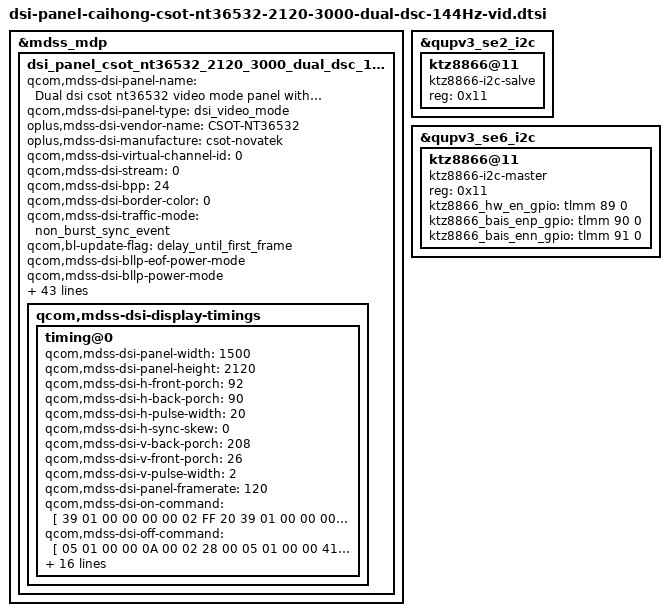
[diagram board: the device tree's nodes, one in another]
&mdss_mdp {
	dsi_panel_csot_nt36532_2120_3000_dual_dsc_144hz_vid: qcom,mdss_dsi_panel_csot_nt36532_2120_3000_dual_dsc_144hz_vid {
		qcom,mdss-dsi-panel-name = "Dual dsi csot nt36532 video mode panel with DSC";
		qcom,mdss-dsi-panel-type = "dsi_video_mode";
		oplus,mdss-dsi-vendor-name = "CSOT-NT36532";
		oplus,mdss-dsi-manufacture = "csot-novatek";
		qcom,mdss-dsi-virtual-channel-id = <0>;
		qcom,mdss-dsi-stream = <0>;
		qcom,mdss-dsi-bpp = <24>;
		qcom,mdss-dsi-border-color = <0>;
		qcom,mdss-dsi-traffic-mode = "non_burst_sync_event";
		qcom,bl-update-flag = "delay_until_first_frame";
		qcom,mdss-dsi-bllp-eof-power-mode;
		qcom,mdss-dsi-bllp-power-mode;
		qcom,mdss-dsi-lane-0-state;
		qcom,mdss-dsi-lane-1-state;
		qcom,mdss-dsi-lane-2-state;
		qcom,mdss-dsi-lane-3-state;
		qcom,mdss-dsi-dma-trigger = "trigger_sw";
		qcom,mdss-dsi-mdp-trigger = "none";
		qcom,mdss-dsi-tx-eot-append;
		qcom,mdss-dsi-lp11-init;
		qcom,mdss-dsi-reset-sequence = <1 10>, <0 5>, <1 10>;
		qcom,mdss-pan-physical-width-dimension = <250>;
		qcom,mdss-pan-physical-height-dimension = <177>;
		/* HDR Setting */
		qcom,mdss-dsi-panel-hdr-enabled;
		qcom,mdss-dsi-panel-hdr-color-primaries = <15635 16450 34000 16000 13250 34500 7500 3000>;
		qcom,mdss-dsi-panel-peak-brightness = <5400000>;
		qcom,mdss-dsi-panel-average-brightness = <2000000>;
		qcom,mdss-dsi-panel-blackness-level = <2047>;

		qcom,mdss-dsi-display-timings {
			timing@0 {
				qcom,mdss-dsi-panel-width = <1500>;
				qcom,mdss-dsi-panel-height = <2120>;
				qcom,mdss-dsi-h-front-porch = <92>;
				qcom,mdss-dsi-h-back-porch = <90>;
				qcom,mdss-dsi-h-pulse-width = <20>;
				qcom,mdss-dsi-h-sync-skew = <0>;
				qcom,mdss-dsi-v-back-porch = <208>;
				qcom,mdss-dsi-v-front-porch = <26>;
				qcom,mdss-dsi-v-pulse-width = <2>;
				qcom,mdss-dsi-panel-framerate = <120>;

				qcom,mdss-dsi-on-command = [
					39 01 00 00 00 00 02 FF 20
					39 01 00 00 00 00 02 FB 01
					39 01 00 00 00 00 02 0D 43
					39 01 00 00 00 00 02 32 72
					39 01 00 00 00 00 02 44 48
					39 01 00 00 00 00 02 58 43
					39 01 00 00 00 00 02 62 36
					39 01 00 00 00 00 02 63 A4
					39 01 00 00 00 00 02 65 CC
					39 01 00 00 00 00 02 69 DD
					39 01 00 00 00 00 02 6D CC
					39 01 00 00 00 00 02 78 93
					39 01 00 00 00 00 02 7C 22
					39 01 00 00 00 00 02 89 6F
					39 01 00 00 00 00 02 8A 6F
					39 01 00 00 00 00 02 8D 6F
					39 01 00 00 00 00 0D EC 4B 4B 4B 4B 5A 5A 5A 5A E1 E1 E1 E1
					39 01 00 00 00 00 02 FF 21
					39 01 00 00 00 00 02 FB 01
					39 01 00 00 00 00 02 BC 00
					39 01 00 00 00 00 02 FF 22
					39 01 00 00 00 00 02 FB 01
					39 01 00 00 00 00 02 6E 13
					39 01 00 00 00 00 02 6F 09
					39 01 00 00 00 00 02 70 97
					39 01 00 00 00 00 02 71 09
					39 01 00 00 00 00 02 73 09
					39 01 00 00 00 00 02 75 7F
					39 01 00 00 00 00 02 76 09
					39 01 00 00 00 00 02 8A 09
					39 01 00 00 00 00 02 8C 09
					39 01 00 00 00 00 02 8E F3
					39 01 00 00 00 00 02 8F 23
					39 01 00 00 00 00 02 90 23
					39 01 00 00 00 00 02 91 23
					39 01 00 00 00 00 02 92 23
					39 01 00 00 00 00 02 93 23
					39 01 00 00 00 00 02 94 0A
					39 01 00 00 00 00 02 95 0A
					39 01 00 00 00 00 02 96 20
					39 01 00 00 00 00 02 9C 0A
					39 01 00 00 00 00 02 9D 20
					39 01 00 00 00 00 02 9E 0A
					39 01 00 00 00 00 02 9F 6A
					39 01 00 00 00 00 02 A0 0B
					39 01 00 00 00 00 02 A6 06
					39 01 00 00 00 00 02 A9 50
					39 01 00 00 00 00 02 AA AD
					39 01 00 00 00 00 02 AB B1
					39 01 00 00 00 00 02 AD 10
					39 01 00 00 00 00 05 B0 0E 0F 0F 0F
					39 01 00 00 00 00 05 B1 ED 63 63 63
					39 01 00 00 00 00 05 B2 0E 0E 0E 0E
					39 01 00 00 00 00 05 B3 11 87 87 87
					39 01 00 00 00 00 05 B4 0E 0F 0F 0F
					39 01 00 00 00 00 05 B5 E9 5F 5F 5F
					39 01 00 00 00 00 02 B8 03
					39 01 00 00 00 00 02 B9 60
					39 01 00 00 00 00 02 BA 60
					39 01 00 00 00 00 02 BB 60
					39 01 00 00 00 00 02 BC 02
					39 01 00 00 00 00 02 BD 60
					39 01 00 00 00 00 02 BE 0B
					39 01 00 00 00 00 02 BF 60
					39 01 00 00 00 00 02 C1 60
					39 01 00 00 00 00 02 C2 06
					39 01 00 00 00 00 02 C3 60
					39 01 00 00 00 00 02 C6 02
					39 01 00 00 00 00 02 C7 58
					39 01 00 00 00 00 02 CA 0A
					39 01 00 00 00 00 02 CB 58
					39 01 00 00 00 00 02 CF 0A
					39 01 00 00 00 00 02 D0 58
					39 01 00 00 00 00 02 D3 0A
					39 01 00 00 00 00 02 D4 58
					39 01 00 00 00 00 02 D8 0B
					39 01 00 00 00 00 02 D9 59
					39 01 00 00 00 00 02 DC 0B
					39 01 00 00 00 00 02 DD 59
					39 01 00 00 00 00 02 E1 0B
					39 01 00 00 00 00 02 E2 59
					39 01 00 00 00 00 02 E6 02
					39 01 00 00 00 00 02 E7 58
					39 01 00 00 00 00 02 EA 0B
					39 01 00 00 00 00 02 EB 59
					39 01 00 00 00 00 02 F3 02
					39 01 00 00 00 00 02 F4 58
					39 01 00 00 00 00 02 F8 FF
					39 01 00 00 00 00 02 F9 FF
					39 01 00 00 00 00 02 FF 23
					39 01 00 00 00 00 02 FB 01
					39 01 00 00 00 00 02 6B 20
					39 01 00 00 00 00 02 6C 0A
					39 01 00 00 00 00 02 6D 20
					39 01 00 00 00 00 02 73 0A
					39 01 00 00 00 00 02 74 0A
					39 01 00 00 00 00 03 75 00 00
					39 01 00 00 00 00 03 76 01 02
					39 01 00 00 00 00 03 77 01 02
					39 01 00 00 00 00 03 78 01 02
					39 01 00 00 00 00 03 7A 63 63
					39 01 00 00 00 00 03 7B B3 B3
					39 01 00 00 00 00 03 7C 2D 32
					39 01 00 00 00 00 03 7E 10 10
					39 01 00 00 00 00 03 BA AD 00
					39 01 00 00 00 00 03 BB AB 00
					39 01 00 00 00 00 04 BC 41 00 00
					39 01 00 00 00 00 02 FF 24
					39 01 00 00 00 00 02 FB 01
					39 01 00 00 00 00 11 00 0C 0D 0E 0F 10 11 12 13 03 25 04 26 27 25 03 24
					39 01 00 00 00 00 09 01 28 03 2C 2E 2C 2E 03 03
					39 01 00 00 00 00 11 02 0C 0D 0E 0F 10 11 12 13 03 25 04 26 27 25 03 24
					39 01 00 00 00 00 09 03 28 03 2C 2E 2C 2E 03 03
					39 01 00 00 00 00 02 1C 80
					39 01 00 00 00 00 02 2F 03
					39 01 00 00 00 00 02 30 03
					39 01 00 00 00 00 02 31 52
					39 01 00 00 00 00 02 33 06
					39 01 00 00 00 00 02 34 07
					39 01 00 00 00 00 02 35 12
					39 01 00 00 00 00 02 37 24
					39 01 00 00 00 00 02 3B 57
					39 01 00 00 00 00 02 3D 01
					39 01 00 00 00 00 02 3F 0B
					39 01 00 00 00 00 02 4B 47
					39 01 00 00 00 00 02 4C 01
					39 01 00 00 00 00 02 50 87
					39 01 00 00 00 00 02 51 21
					39 01 00 00 00 00 02 52 43
					39 01 00 00 00 00 02 53 65
					39 01 00 00 00 00 02 54 87
					39 01 00 00 00 00 03 55 02 01
					39 01 00 00 00 00 02 56 08
					39 01 00 00 00 00 02 58 10
					39 01 00 00 00 00 02 59 10
					39 01 00 00 00 00 02 5A 09
					39 01 00 00 00 00 02 5B 53
					39 01 00 00 00 00 03 5E 00 06
					39 01 00 00 00 00 03 60 81 77
					39 01 00 00 00 00 02 61 48
					39 01 00 00 00 00 02 67 21
					39 01 00 00 00 00 02 68 43
					39 01 00 00 00 00 02 6B 34
					39 01 00 00 00 00 02 6C 12
					39 01 00 00 00 00 02 71 04
					39 01 00 00 00 00 02 7E 20
					39 01 00 00 00 00 02 7F E1
					39 01 00 00 00 00 04 92 5E 00 FE
					39 01 00 00 00 00 03 93 1A 00
					39 01 00 00 00 00 03 94 D2 00
					39 01 00 00 00 00 02 95 09
					39 01 00 00 00 00 04 96 20 AA 00
					39 01 00 00 00 00 02 97 C0
					39 01 00 00 00 00 02 98 80
					39 01 00 00 00 00 02 9A 0A
					39 01 00 00 00 00 02 A5 00
					39 01 00 00 00 00 04 AA A9 A9 2A
					39 01 00 00 00 00 02 AB 26
					39 01 00 00 00 00 04 B6 08 08 00
					39 01 00 00 00 00 04 C2 CC 00 01
					39 01 00 00 00 00 02 C3 00
					39 01 00 00 00 00 02 C4 2F
					39 01 00 00 00 00 02 D4 03
					39 01 00 00 00 00 02 D6 46
					39 01 00 00 00 00 02 D7 25
					39 01 00 00 00 00 02 D9 21
					39 01 00 00 00 00 02 DB 39
					39 01 00 00 00 00 02 DD 44
					39 01 00 00 00 00 02 DF 09
					39 01 00 00 00 00 02 E1 09
					39 01 00 00 00 00 02 E3 09
					39 01 00 00 00 00 02 E5 09
					39 01 00 00 00 00 02 E9 09
					39 01 00 00 00 00 02 EB 09
					39 01 00 00 00 00 02 EF 09
					39 01 00 00 00 00 02 F1 23
					39 01 00 00 00 00 02 F2 23
					39 01 00 00 00 00 02 F3 23
					39 01 00 00 00 00 02 F4 22
					39 01 00 00 00 00 02 F5 23
					39 01 00 00 00 00 02 F6 23
					39 01 00 00 00 00 02 FF 25
					39 01 00 00 00 00 02 FB 01
					39 01 00 00 00 00 02 05 00
					39 01 00 00 00 00 02 0F 20
					39 01 00 00 00 00 02 13 01
					39 01 00 00 00 00 02 14 FD
					39 01 00 00 00 00 02 15 01
					39 01 00 00 00 00 02 16 A8
					39 01 00 00 00 00 02 1F 09
					39 01 00 00 00 00 02 20 53
					39 01 00 00 00 00 02 23 0A
					39 01 00 00 00 00 02 24 20
					39 01 00 00 00 00 02 26 09
					39 01 00 00 00 00 02 27 53
					39 01 00 00 00 00 02 2A 0A
					39 01 00 00 00 00 02 2B 20
					39 01 00 00 00 00 02 31 20
					39 01 00 00 00 00 02 33 0B
					39 01 00 00 00 00 02 34 58
					39 01 00 00 00 00 02 37 0A
					39 01 00 00 00 00 02 38 20
					39 01 00 00 00 00 02 39 0A
					39 01 00 00 00 00 02 3A 02
					39 01 00 00 00 00 02 3F 20
					39 01 00 00 00 00 02 40 00
					39 01 00 00 00 00 02 42 0A
					39 01 00 00 00 00 02 45 57
					39 01 00 00 00 00 02 47 47
					39 01 00 00 00 00 02 48 0B
					39 01 00 00 00 00 02 49 58
					39 01 00 00 00 00 02 4C 0A
					39 01 00 00 00 00 02 4D 20
					39 01 00 00 00 00 02 4E 0A
					39 01 00 00 00 00 02 50 0B
					39 01 00 00 00 00 02 51 58
					39 01 00 00 00 00 02 54 0A
					39 01 00 00 00 00 02 55 20
					39 01 00 00 00 00 02 56 0A
					39 01 00 00 00 00 02 5B A0
					39 01 00 00 00 00 02 5E 57
					39 01 00 00 00 00 02 60 47
					39 01 00 00 00 00 02 61 0B
					39 01 00 00 00 00 02 62 58
					39 01 00 00 00 00 02 65 0A
					39 01 00 00 00 00 02 66 20
					39 01 00 00 00 00 02 67 0A
					39 01 00 00 00 00 02 68 06
					39 01 00 00 00 00 02 6A 06
					39 01 00 00 00 00 02 6B 04
					39 01 00 00 00 00 02 6C 0E
					39 01 00 00 00 00 02 6D 0E
					39 01 00 00 00 00 02 6E 12
					39 01 00 00 00 00 02 6F 12
					39 01 00 00 00 00 02 BC 01
					39 01 00 00 00 00 02 BD FD
					39 01 00 00 00 00 02 C0 0C
					39 01 00 00 00 00 02 C1 46
					39 01 00 00 00 00 02 C2 A5
					39 01 00 00 00 00 02 C5 1F
					39 01 00 00 00 00 02 C6 10
					39 01 00 00 00 00 02 DB 03
					39 01 00 00 00 00 02 DC 18
					39 01 00 00 00 00 02 DD 02
					39 01 00 00 00 00 02 DE 94
					39 01 00 00 00 00 02 ED 80
					39 01 00 00 00 00 02 F6 03
					39 01 00 00 00 00 02 F7 18
					39 01 00 00 00 00 02 FF 26
					39 01 00 00 00 00 02 FB 01
					39 01 00 00 00 00 02 04 6A
					39 01 00 00 00 00 02 06 9B
					39 01 00 00 00 00 02 0A 05
					39 01 00 00 00 00 02 0C 06
					39 01 00 00 00 00 02 0D 03
					39 01 00 00 00 00 02 0F 00
					39 01 00 00 00 00 02 11 05
					39 01 00 00 00 00 02 12 51
					39 01 00 00 00 00 02 13 30
					39 01 00 00 00 00 02 14 28
					39 01 00 00 00 00 02 16 11
					39 01 00 00 00 00 05 19 20 1F 20 20
					39 01 00 00 00 00 05 1A 70 75 70 70
					39 01 00 00 00 00 05 1B 1F 1E 1F 1F
					39 01 00 00 00 00 05 1C 8F 94 8F 8F
					39 01 00 00 00 00 02 1D 00
					39 01 00 00 00 00 02 1E 5E
					39 01 00 00 00 00 02 1F 5E
					39 01 00 00 00 00 02 24 02
					39 01 00 00 00 00 02 25 5E
					39 01 00 00 00 00 02 26 26
					39 01 00 00 00 00 05 2A 20 1F 20 20
					39 01 00 00 00 00 05 2B 67 6C 67 67
					39 01 00 00 00 00 0A 2D 00 00 00 0E 00 00 0F 04 00
					39 01 00 00 00 00 02 2F 0B
					39 01 00 00 00 00 02 30 5E
					39 01 00 00 00 00 02 32 5E
					39 01 00 00 00 00 02 33 22
					39 01 00 00 00 00 02 34 92
					39 01 00 00 00 00 02 35 78
					39 01 00 00 00 00 02 36 96
					39 01 00 00 00 00 02 37 78
					39 01 00 00 00 00 02 38 06
					39 01 00 00 00 00 02 39 06
					39 01 00 00 00 00 02 3A 5E
					39 01 00 00 00 00 07 3D 00 A0 2A 00 00 00
					39 01 00 00 00 00 02 40 5A
					39 01 00 00 00 00 02 41 5A
					39 01 00 00 00 00 02 42 5A
					39 01 00 00 00 00 02 43 02
					39 01 00 00 00 00 02 44 5A
					39 01 00 00 00 00 02 45 0B
					39 01 00 00 00 00 02 46 5A
					39 01 00 00 00 00 02 48 5A
					39 01 00 00 00 00 02 49 06
					39 01 00 00 00 00 02 4A 5A
					39 01 00 00 00 00 02 4D 02
					39 01 00 00 00 00 02 4E 51
					39 01 00 00 00 00 02 4F 02
					39 01 00 00 00 00 02 50 47
					39 01 00 00 00 00 02 51 0A
					39 01 00 00 00 00 02 52 51
					39 01 00 00 00 00 02 53 02
					39 01 00 00 00 00 02 54 72
					39 01 00 00 00 00 02 56 0A
					39 01 00 00 00 00 02 58 51
					39 01 00 00 00 00 02 5B 0A
					39 01 00 00 00 00 02 5C 51
					39 01 00 00 00 00 02 60 0B
					39 01 00 00 00 00 02 61 52
					39 01 00 00 00 00 02 64 0B
					39 01 00 00 00 00 02 65 52
					39 01 00 00 00 00 02 69 0B
					39 01 00 00 00 00 02 6A 52
					39 01 00 00 00 00 02 6E 02
					39 01 00 00 00 00 02 6F 51
					39 01 00 00 00 00 02 70 02
					39 01 00 00 00 00 02 71 47
					39 01 00 00 00 00 02 72 0B
					39 01 00 00 00 00 02 73 52
					39 01 00 00 00 00 02 74 02
					39 01 00 00 00 00 02 75 72
					39 01 00 00 00 00 02 7B 02
					39 01 00 00 00 00 02 7C 51
					39 01 00 00 00 00 02 7E 02
					39 01 00 00 00 00 02 7F 47
					39 01 00 00 00 00 02 80 CC
					39 01 00 00 00 00 02 81 CC
					39 01 00 00 00 00 05 82 00 64 64 64
					39 01 00 00 00 00 04 84 1E 1E 1E
					39 01 00 00 00 00 04 85 20 20 20
					39 01 00 00 00 00 02 8B 7F
					39 01 00 00 00 00 02 8C 05
					39 01 00 00 00 00 02 8D 00
					39 01 00 00 00 00 02 8F 00
					39 01 00 00 00 00 02 92 51
					39 01 00 00 00 00 02 93 5E
					39 01 00 00 00 00 02 94 62
					39 01 00 00 00 00 02 96 11
					39 01 00 00 00 00 03 97 00 00
					39 01 00 00 00 00 05 99 0E 0F 0F 0F
					39 01 00 00 00 00 05 9A F3 2C 2C 2C
					39 01 00 00 00 00 05 9C 17 50 50 50
					39 01 00 00 00 00 05 9D 0E 0F 0F 0F
					39 01 00 00 00 00 05 9E EF 28 28 28
					39 01 00 00 00 00 03 CD 39 94
					39 01 00 00 00 00 03 CE 34 94
					39 01 00 00 00 00 04 CF 01 00 39
					39 01 00 00 00 00 03 D0 00 00
					39 01 00 00 00 00 03 D1 00 00
					39 01 00 00 00 00 02 D2 2D
					39 01 00 00 00 00 02 FF 27
					39 01 00 00 00 00 02 FB 01
					39 01 00 00 00 00 02 00 80
					39 01 00 00 00 00 02 01 8C
					39 01 00 00 00 00 02 03 D0
					39 01 00 00 00 00 02 05 28
					39 01 00 00 00 00 02 06 0C
					39 01 00 00 00 00 02 07 03
					39 01 00 00 00 00 03 08 98 0A
					39 01 00 00 00 00 03 09 2E 00
					39 01 00 00 00 00 03 0A BB 00
					39 01 00 00 00 00 03 0B 24 00
					39 01 00 00 00 00 03 0C 28 00
					39 01 00 00 00 00 03 0D 29 00
					39 01 00 00 00 00 03 0E BB 00
					39 01 00 00 00 00 03 0F 24 00
					39 01 00 00 00 00 03 10 28 00
					39 01 00 00 00 00 02 13 06
					39 01 00 00 00 00 02 30 A0
					39 01 00 00 00 00 03 31 3F 00
					39 01 00 00 00 00 02 50 00
					39 01 00 00 00 00 02 58 80
					39 01 00 00 00 00 02 59 00
					39 01 00 00 00 00 02 5A 00
					39 01 00 00 00 00 02 5B CC
					39 01 00 00 00 00 02 5C 00
					39 01 00 00 00 00 02 5D 00
					39 01 00 00 00 00 02 5E 00
					39 01 00 00 00 00 02 5F 00
					39 01 00 00 00 00 03 60 00 00
					39 01 00 00 00 00 03 61 00 00
					39 01 00 00 00 00 03 62 00 00
					39 01 00 00 00 00 03 63 00 00
					39 01 00 00 00 00 03 64 00 00
					39 01 00 00 00 00 03 65 00 00
					39 01 00 00 00 00 03 66 00 00
					39 01 00 00 00 00 03 67 00 00
					39 01 00 00 00 00 03 68 00 00
					39 01 00 00 00 00 02 76 F0
					39 01 00 00 00 00 03 77 2A 20
					39 01 00 00 00 00 02 78 80
					39 01 00 00 00 00 02 79 D5
					39 01 00 00 00 00 02 7A 00
					39 01 00 00 00 00 02 7B D0
					39 01 00 00 00 00 02 7D 04
					39 01 00 00 00 00 02 7E 51
					39 01 00 00 00 00 02 7F 04
					39 01 00 00 00 00 03 80 39 09
					39 01 00 00 00 00 03 81 32 00
					39 01 00 00 00 00 03 82 6C 40
					39 01 00 00 00 00 03 83 17 00
					39 01 00 00 00 00 03 84 2B 00
					39 01 00 00 00 00 03 85 2C 00
					39 01 00 00 00 00 03 86 6C 40
					39 01 00 00 00 00 03 87 17 00
					39 01 00 00 00 00 03 88 2B 00
					39 01 00 00 00 00 02 96 F0
					39 01 00 00 00 00 03 97 2A 00
					39 01 00 00 00 00 02 D1 54
					39 01 00 00 00 00 02 FF 2A
					39 01 00 00 00 00 02 FB 01
					39 01 00 00 00 00 02 00 13
					39 01 00 00 00 00 02 01 09
					39 01 00 00 00 00 02 02 99
					39 01 00 00 00 00 02 03 09
					39 01 00 00 00 00 02 05 09
					39 01 00 00 00 00 02 07 7F
					39 01 00 00 00 00 02 08 09
					39 01 00 00 00 00 02 0A 09
					39 01 00 00 00 00 02 0C 09
					39 01 00 00 00 00 02 0E 23
					39 01 00 00 00 00 02 0F 23
					39 01 00 00 00 00 02 10 23
					39 01 00 00 00 00 02 11 23
					39 01 00 00 00 00 02 12 23
					39 01 00 00 00 00 02 13 23
					39 01 00 00 00 00 02 14 0A
					39 01 00 00 00 00 02 15 0A
					39 01 00 00 00 00 02 16 1E
					39 01 00 00 00 00 02 17 0A
					39 01 00 00 00 00 02 18 1E
					39 01 00 00 00 00 02 19 0A
					39 01 00 00 00 00 02 1A 1E
					39 01 00 00 00 00 02 1B 0A
					39 01 00 00 00 00 02 1C 1E
					39 01 00 00 00 00 02 1E 0A
					39 01 00 00 00 00 02 1F 0A
					39 01 00 00 00 00 02 25 15
					39 01 00 00 00 00 02 27 5F
					39 01 00 00 00 00 02 28 78
					39 01 00 00 00 00 04 2F 44 21 02
					39 01 00 00 00 00 02 30 02
					39 01 00 00 00 00 02 32 75
					39 01 00 00 00 00 02 33 7F
					39 01 00 00 00 00 02 35 00
					39 01 00 00 00 00 0E 4B 00 00 00 00 00 00 00 00 00 00 00 00 00
					39 01 00 00 00 00 02 64 BE
					39 01 00 00 00 00 02 67 16
					39 01 00 00 00 00 02 68 00
					39 01 00 00 00 00 02 69 00
					39 01 00 00 00 00 02 6A B6
					39 01 00 00 00 00 02 6B 00
					39 01 00 00 00 00 02 6C 00
					39 01 00 00 00 00 02 79 B6
					39 01 00 00 00 00 02 7C 36
					39 01 00 00 00 00 02 7F BE
					39 01 00 00 00 00 02 82 36
					39 01 00 00 00 00 02 85 3E
					39 01 00 00 00 00 02 88 16
					39 01 00 00 00 00 02 89 00
					39 01 00 00 00 00 02 8A 00
					39 01 00 00 00 00 02 8B 16
					39 01 00 00 00 00 02 8C 00
					39 01 00 00 00 00 02 8D 00
					39 01 00 00 00 00 02 8E 16
					39 01 00 00 00 00 02 8F 00
					39 01 00 00 00 00 02 90 00
					39 01 00 00 00 00 02 91 BE
					39 01 00 00 00 00 02 92 00
					39 01 00 00 00 00 02 93 00
					39 01 00 00 00 00 02 94 06
					39 01 00 00 00 00 02 99 91
					39 01 00 00 00 00 02 9A 0A
					39 01 00 00 00 00 02 A2 33
					39 01 00 00 00 00 02 A4 03
					39 01 00 00 00 00 02 A5 C0
					39 01 00 00 00 00 02 A9 21
					39 01 00 00 00 00 03 B1 00 01
					39 01 00 00 00 00 04 B3 16 00 00
					39 01 00 00 00 00 02 B7 FF
					39 01 00 00 00 00 02 B8 40
					39 01 00 00 00 00 0C B9 98 00 76 00 12 BA 3E 5F 41 02 00
					39 01 00 00 00 00 09 BA AA AA A5 A5 E1 E1 FF FF
					39 01 00 00 00 00 11 BB AA AA AA AA AA 55 AA 55 38 C7 38 C7 FF FF FF FF
					39 01 00 00 00 00 03 BC 66 06
					39 01 00 00 00 00 02 C4 02
					39 01 00 00 00 00 02 C5 0A
					39 01 00 00 00 00 02 C6 20
					39 01 00 00 00 00 02 C8 07
					39 01 00 00 00 00 02 CA 01
					39 01 00 00 00 00 05 CB 11 00 00 00
					39 01 00 00 00 00 07 CC A5 5A 00 A5 5A 00
					39 01 00 00 00 00 02 D0 04
					39 01 00 00 00 00 02 D1 81
					39 01 00 00 00 00 02 DB 00
					39 01 00 00 00 00 02 F4 91
					39 01 00 00 00 00 02 F5 0A
					39 01 00 00 00 00 02 FF F0
					39 01 00 00 00 00 02 FB 01
					39 01 00 00 00 00 02 FA 05
					39 01 00 00 00 00 02 76 16
					39 01 00 00 00 00 02 FF 10
					39 01 00 00 00 00 02 FB 01
					39 01 00 00 00 00 07 3B 03 D2 1A 04 04 00
					39 01 00 00 00 00 02 90 03
					39 01 00 00 00 00 11 91 89 A8 00 14 D2 00 00 00 02 1E 00 0A 05 7A 03 AA
					39 01 00 00 00 00 03 92 10 F0
					39 01 00 00 00 00 02 9D 01
					39 01 00 00 00 00 02 B2 91
					39 01 00 00 00 00 02 B3 40

					15 01 00 00 00 00 02 FF 27
					15 01 00 00 00 00 02 FB 01
					15 01 00 00 00 00 02 D0 31
					15 01 00 00 00 00 02 D1 54
					15 01 00 00 00 00 02 DE 42
					15 01 00 00 00 00 02 DF 02
					15 01 00 00 00 00 02 FF 10
					15 01 00 00 00 00 02 FB 01
					05 01 00 00 78 00 02 11 00
					05 01 00 00 0A 00 02 29 00
				];
				qcom,mdss-dsi-off-command = [
					05 01 00 00 0A 00 02 28 00
					05 01 00 00 41 00 02 10 00
				];
				qcom,mdss-dsi-on-command-state = "dsi_lp_mode";
				qcom,mdss-dsi-off-command-state = "dsi_lp_mode";
				qcom,mdss-dsi-h-sync-pulse = <0>;
				qcom,compression-mode = "dsc";
				qcom,mdss-dsc-version = <0x12>;
				qcom,mdss-dsc-encoders = <1>;
				qcom,mdss-dsc-slice-height = <20>;
				qcom,mdss-dsc-slice-width = <750>;
				qcom,mdss-dsc-slice-per-pkt = <2>;
				qcom,mdss-dsc-bit-per-component = <8>;
				qcom,mdss-dsc-bit-per-pixel = <8>;
				qcom,mdss-dsc-block-prediction-enable;
			};
		};
	};
};

&dsi_panel_csot_nt36532_2120_3000_dual_dsc_144hz_vid {
	qcom,panel-supply-entries = <&oplus_dsi_panel_custom_pwr_supply>;
	qcom,dsi-ctrl-num = <0 1>;
	qcom,dsi-phy-num = <0 1>;
	qcom,dsi-select-clocks = "pll_byte_clk0", "pll_dsi_clk0";
	qcom,mdss-dsi-bl-pmic-control-type = "bl_ctrl_external";
	qcom,mdss-dsi-bl-min-level = <2>;
	qcom,mdss-dsi-bl-max-level = <2047>;
	qcom,mdss-brightness-max-level = <2047>;
	qcom,mdss-dsi-bl-inverted-dbv;
	oplus,dsi-brightness-default-level = <717>;
	qcom,platform-reset-gpio = <&tlmm 133 0>;
	qcom,esd-check-enabled;
	qcom,mdss-dsi-panel-status-check-mode = "error_flag";
	qcom,error-flag-gpio = <&tlmm 86 0>;
	qcom,error-flag-gpio-slave = <&tlmm 43 0>;
	oplus,bl-use-ktz8866-ic-ctrl;
	oplus,dp-enabled;

	qcom,mdss-dsi-pan-enable-dynamic-fps;
	qcom,mdss-dsi-pan-fps-update = "dfps_immediate_porch_mode_vfp";
	qcom,dsi-supported-dfps-list = <120 60 30>;

	qcom,mdss-dsi-display-timings {
		timing@0 {
			qcom,mdss-dsi-panel-phy-timings = [00 27 0A 0A 1B 19 0A
				0B 0A 02 04 00 20 0F];
			qcom,display-topology = <2 2 2>;
			qcom,default-topology-index = <0>;
		};
	};
};

&qupv3_se2_i2c {
	status = "ok";
	ktz8866@11 {
		compatible = "ktz8866-i2c-salve";
		reg = <0x11>;
	};
};

&qupv3_se6_i2c {
	status = "ok";
	ktz8866@11 {
		compatible = "ktz8866-i2c-master";
		reg = <0x11>;
		ktz8866_hw_en_gpio = <&tlmm 89 0>;
		ktz8866_bais_enp_gpio = <&tlmm 90 0>;
		ktz8866_bais_enn_gpio = <&tlmm 91 0>;
	};
};
